# ipro6s register map
Vendor: intelpro; Series: IPRO6S
CPU: ipro6s, little endian
Registers are 32-bit, read-write, reset 0x0 unless marked. A register's access mark holds for its fields unless they carry their own. Offsets are from the block's base; [hi:lo] are bit positions.

## CCI
Base 0x30008000
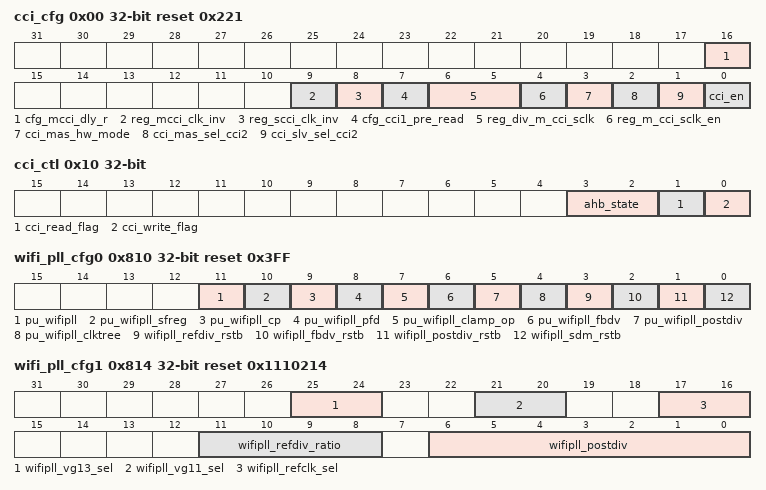
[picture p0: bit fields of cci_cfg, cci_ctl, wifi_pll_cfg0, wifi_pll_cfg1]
0x00 cci_cfg reset 0x221
  [16] cfg_mcci_dly_r — delay CCI Master Read Data 0 : no delay 1: delay 1T
  [9] reg_mcci_clk_inv — 1: Invert MCCI Clk Out 0: No Invert MCCI Clk Out
  [8] reg_scci_clk_inv — 1 : Invert SCCI CLK IN 0 : No Invert SCCI CLK IN
  [7] cfg_cci1_pre_read — Set 1 to let CCI1 issue AHB Read immediately after address phase to save timing
  [6:5] reg_div_m_cci_sclk — CCI Master Port Clock Divier ( Freq of HCLK / N+1)
  [4] reg_m_cci_sclk_en — CCI Master Port Clock Out Control
  [3] cci_mas_hw_mode — CCI Master Port controlled by : 0 : APB Mode, 1: HW Mode
  [2] cci_mas_sel_cci2 — CCI Master Out Select ( 0: CCI1, 1: CCI2)
  [1] cci_slv_sel_cci2 — CCI Slave Out Select ( 0: CCI1, 1: CCI2)
  [0] cci_en — Enable CCI
0x04 cci_addr
  [31:0] apb_cci_addr — Address Control for CCI Master Port (APB Mode)
0x08 cci_wdata
  [31:0] apb_cci_wdata — Write data to CCI Master Port (APB Mode)
0x0C cci_rdata reset not defined
  [31:0] apb_cci_rdata ro — Read data from CCI Master Port (APB Mode)
0x10 cci_ctl reset not defined
  [3:2] ahb_state ro — AHB Bus Info
  [1] cci_read_flag ro — Write 1 to trigger CCI read
  [0] cci_write_flag ro — Write 1 to trigger CCI write
0x810 wifi_pll_cfg0 reset 0x3FF
  [11] pu_wifipll — 1'b1: power up clock PLL
  [10] pu_wifipll_sfreg — 1'b1: power up clock PLL source follow regular
  [9] pu_wifipll_cp
  [8] pu_wifipll_pfd
  [7] pu_wifipll_clamp_op
  [6] pu_wifipll_fbdv
  [5] pu_wifipll_postdiv
  [4] pu_wifipll_clktree
  [3] wifipll_refdiv_rstb
  [2] wifipll_fbdv_rstb
  [1] wifipll_postdiv_rstb
  [0] wifipll_sdm_rstb
0x814 wifi_pll_cfg1 reset 0x1110214
  [25:24] wifipll_vg13_sel — 0:1.25V; 1:1.3V; 2:1.35V; 3:1.4V
  [21:20] wifipll_vg11_sel — 0:vdd13-0.15V; 1:vdd13-0.2V; 2:vdd13-0.25V; 3:vdd13-0.3V
  [17:16] wifipll_refclk_sel — default 0: xtal_soc_clk; 1: xtal_clk; 2: xtal_lo_clk; 3: rc32M_clk
  [11:8] wifipll_refdiv_ratio
  [6:0] wifipll_postdiv — >=8 and should be even number
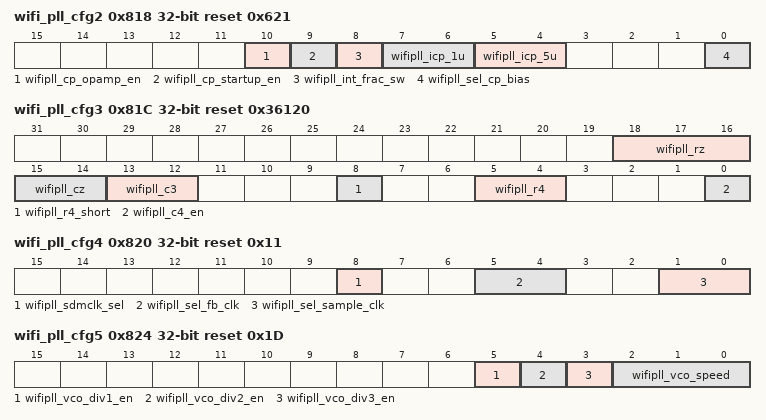
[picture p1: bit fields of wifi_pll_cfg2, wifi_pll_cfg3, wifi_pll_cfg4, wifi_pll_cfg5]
0x818 wifi_pll_cfg2 reset 0x621
  [10] wifipll_cp_opamp_en
  [9] wifipll_cp_startup_en
  [8] wifipll_int_frac_sw — int mode:0; frac mode:1
  [7:6] wifipll_icp_1u — int mode:0; frac mode:1
  [5:4] wifipll_icp_5u — int mode:2; frac mode:0
  [0] wifipll_sel_cp_bias — 0:traditional cp; 1:clamp_op cp
0x81C wifi_pll_cfg3 reset 0x36120
  [18:16] wifipll_rz — int mode=3, 18K; frac mode = 5, 40.7K
  [15:14] wifipll_cz — int mode=1, 29pF; frac_mode = 2, 32pF
  [13:12] wifipll_c3 — int:2; frac:2
  [8] wifipll_r4_short — int:1; frac:0
  [5:4] wifipll_r4 — int:2; frac:2
  [0] wifipll_c4_en — int:0; frac:1
0x820 wifi_pll_cfg4 reset 0x11
  [8] wifipll_sdmclk_sel — default 0: fbclk; 1: sample clock(pclk)
  [5:4] wifipll_sel_fb_clk — 0:mod1; 1:mod2; 2:mod3
  [1:0] wifipll_sel_sample_clk — 0:[8,32)mod2; 1:[16:64)mod3; 2:[32,128)mod4
0x824 wifi_pll_cfg5 reset 0x1D
  [5] wifipll_vco_div1_en — 1: enable vcobuf 960MHz output
  [4] wifipll_vco_div2_en — 1: enable vcobuf 480MHz output
  [3] wifipll_vco_div3_en — 1: enable vcobuf 320MHz output
  [2:0] wifipll_vco_speed — 5: 960M
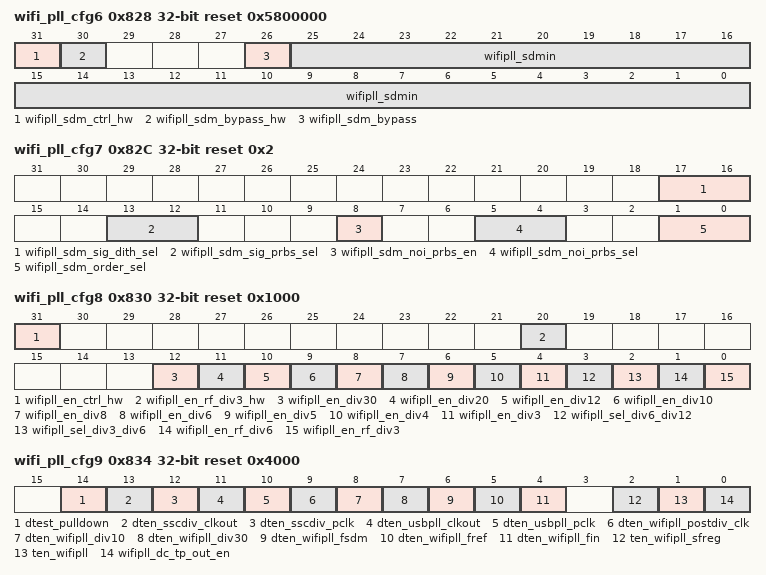
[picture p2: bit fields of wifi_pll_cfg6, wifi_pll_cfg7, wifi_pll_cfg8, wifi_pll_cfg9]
0x828 wifi_pll_cfg6 reset 0x5800000 (reset mask 0x87FFFFFF)
  [31] wifipll_sdm_ctrl_hw — 1:enable hw control
  [30] wifipll_sdm_bypass_hw ro
  [26] wifipll_sdm_bypass — 1:bypass sdm,default hw control from rf_top
  [25:0] wifipll_sdmin — U(26,19), default 40M crystal, refdiv=2, divratio=48
0x82C wifi_pll_cfg7 reset 0x2
  [17:16] wifipll_sdm_sig_dith_sel
  [13:12] wifipll_sdm_sig_prbs_sel
  [8] wifipll_sdm_noi_prbs_en
  [5:4] wifipll_sdm_noi_prbs_sel
  [1:0] wifipll_sdm_order_sel — 0: 1st order, 1: 2nd order, 2 or 3: 3nd order
0x830 wifi_pll_cfg8 reset 0x1000 (reset mask 0x80001FFF)
  [31] wifipll_en_ctrl_hw — 1:enable hw control
  [20] wifipll_en_rf_div3_hw ro
  [12] wifipll_en_div30 — 1: enable wifipll_div30 output
  [11] wifipll_en_div20 — 1: enable wifipll_div20 output
  [10] wifipll_en_div12 — 1: enable wifipll_div12 output
  [9] wifipll_en_div10 — 1: enable wifipll_div10 output
  [8] wifipll_en_div8 — 1: enable wifipll_div8 output
  [7] wifipll_en_div6 — 1: enable wifipll_div6 output
  [6] wifipll_en_div5 — 1: enable wifipll_div5 output, 40% duty cycle
  [5] wifipll_en_div4 — 1: enable wifipll_div4 output
  [4] wifipll_en_div3 — 1: enable wifipll_div3 output
  [3] wifipll_sel_div6_div12 — 1: wifipll_div3_rf = 80M 0: wifipll_div3_rf = 160M For Long range mode
  [2] wifipll_sel_div3_div6 — 1: wifipll_div3_rf = 160M 0: wifipll_div3_rf = 320M For Long range mode
  [1] wifipll_en_rf_div6 — 1: enable wifipll_div6_rf output
  [0] wifipll_en_rf_div3 — 1: enable wifipll_div3_rf output, default controlled by wifi rf state (wifipll_en_ctrl_hw)
0x834 wifi_pll_cfg9 reset 0x4000
  [14] dtest_pulldown, [13] dten_sscdiv_clkout, [12] dten_sscdiv_pclk, [11] dten_usbpll_clkout, [10] dten_usbpll_pclk, [9] dten_wifipll_postdiv_clk, [8] dten_wifipll_div10, [7] dten_wifipll_div30, [6] dten_wifipll_fsdm, [5] dten_wifipll_fref, [4] dten_wifipll_fin, [2] ten_wifipll_sfreg, [1] ten_wifipll, [0] wifipll_dc_tp_out_en
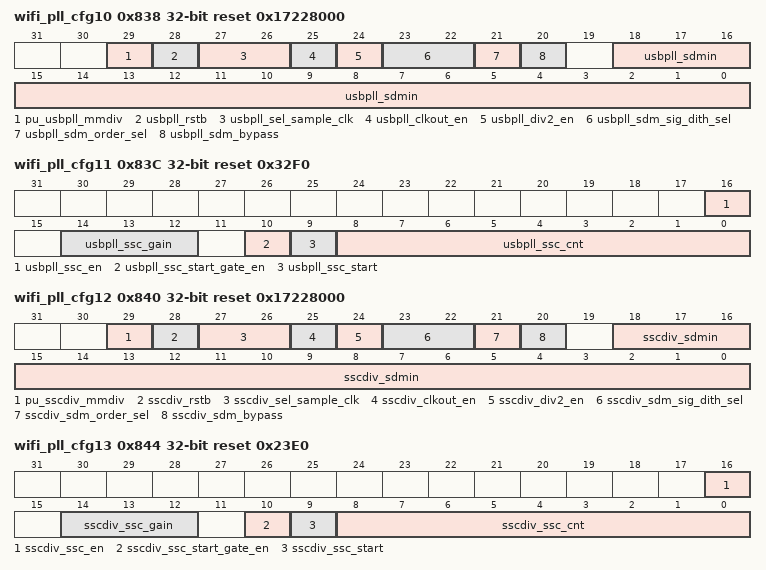
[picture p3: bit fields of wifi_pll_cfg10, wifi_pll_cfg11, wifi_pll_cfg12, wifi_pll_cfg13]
0x838 wifi_pll_cfg10 reset 0x17228000
  [29] pu_usbpll_mmdiv
  [28] usbpll_rstb
  [27:26] usbpll_sel_sample_clk
  [25] usbpll_clkout_en
  [24] usbpll_div2_en — 1: enable /2 divider @ output to ensure near 50% duty cycle
  [23:22] usbpll_sdm_sig_dith_sel
  [21] usbpll_sdm_order_sel
  [20] usbpll_sdm_bypass
  [18:0] usbpll_sdmin — u(19,13), input clock 480M, output clock 12M, 480M/12M/2=20
0x83C wifi_pll_cfg11 reset 0x32F0
  [16] usbpll_ssc_en
  [14:12] usbpll_ssc_gain — 3: assc = 0.6%
  [10] usbpll_ssc_start_gate_en
  [9] usbpll_ssc_start
  [8:0] usbpll_ssc_cnt — 240: fssc=50kHz
0x840 wifi_pll_cfg12 reset 0x17228000
  [29] pu_sscdiv_mmdiv
  [28] sscdiv_rstb
  [27:26] sscdiv_sel_sample_clk
  [25] sscdiv_clkout_en
  [24] sscdiv_div2_en — 1: enable /2 divider @ output to ensure near 50% duty cycle
  [23:22] sscdiv_sdm_sig_dith_sel
  [21] sscdiv_sdm_order_sel
  [20] sscdiv_sdm_bypass
  [18:0] sscdiv_sdmin — u(19,13), input clock 480M, output clock 12M, 480M/12M/2=20
0x844 wifi_pll_cfg13 reset 0x23E0
  [16] sscdiv_ssc_en
  [14:12] sscdiv_ssc_gain — 3: assc = 0.6%
  [10] sscdiv_ssc_start_gate_en
  [9] sscdiv_ssc_start
  [8:0] sscdiv_ssc_cnt — 480: fssc=50kHz
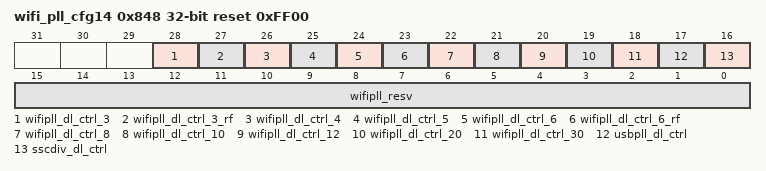
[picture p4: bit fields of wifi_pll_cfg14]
0x848 wifi_pll_cfg14 reset 0xFF00
  [28] wifipll_dl_ctrl_3, [27] wifipll_dl_ctrl_3_rf, [26] wifipll_dl_ctrl_4, [25] wifipll_dl_ctrl_5, [24] wifipll_dl_ctrl_6, [23] wifipll_dl_ctrl_6_rf, [22] wifipll_dl_ctrl_8, [21] wifipll_dl_ctrl_10, [20] wifipll_dl_ctrl_12, [19] wifipll_dl_ctrl_20, [18] wifipll_dl_ctrl_30, [17] usbpll_dl_ctrl, [16] sscdiv_dl_ctrl, [15:0] wifipll_resv
